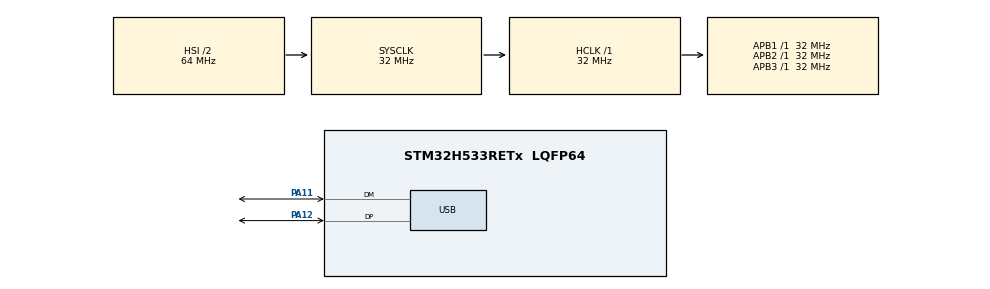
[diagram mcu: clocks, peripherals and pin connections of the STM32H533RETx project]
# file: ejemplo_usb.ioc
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BOOTPATH.BootPathName=LEGACY
BOOTPATH.UserSelectedBootPath=LEGACY
CORTEX_M33_NS.Number-Cortex_Memory_Protection_Unit_Region0_OTP_RO_AREAS_Settings=MPU_REGION_NUMBER0
CORTEX_M33_NS.default_mode_Activation=1
CORTEX_M33_NS.userName=CORTEX_M33
Mcu.Family=STM32H5
Mcu.Name=STM32H533RETx
Mcu.Package=LQFP64
NUCLEO-H533RE.LD4=true
NUCLEO-H533RE.VCP=true
NVIC.PriorityGroup=NVIC_PRIORITYGROUP_4
NVIC.USB_DRD_FS_IRQn=true\:0\:0\:false\:false\:true\:true\:true\:true
PA11.Mode=Device
PA11.Signal=USB_DM
PA12.Mode=Device
PA12.Signal=USB_DP
PA13(JTMS/SWDIO).GPIO_Label=SWDIO
PA13(JTMS/SWDIO).Signal=DEBUG_JTMS-SWDIO
PA14(JTCK/SWCLK).GPIO_Label=SWCLK
PA14(JTCK/SWCLK).Signal=DEBUG_JTCK-SWCLK
PA15(JTDI).GPIO_Label=JTDI
PA15(JTDI).Signal=DEBUG_JTDI
PA2.Signal=USART2_TX
PA3.Signal=USART2_RX
PB3(JTDO/TRACESWO).GPIO_Label=SWO
PB3(JTDO/TRACESWO).Signal=DEBUG_JTDO-SWO
ProjectManager.HeapSize=0x200
ProjectManager.StackSize=0x400
ProjectManager.TargetToolchain=STM32CubeIDE
RCC.ADCFreq_Value=32000000
RCC.AHBFreq_Value=32000000
RCC.APB1Freq_Value=32000000
RCC.APB1TimFreq_Value=32000000
RCC.APB2Freq_Value=32000000
RCC.APB2TimFreq_Value=32000000
RCC.APB3Freq_Value=32000000
RCC.CSI_VALUE=4000000
RCC.CortexFreq_Value=32000000
RCC.EPOD_VALUE=4000000
RCC.HCLKFreq_Value=32000000
RCC.HSE_VALUE=25000000
RCC.HSI48_VALUE=48000000
RCC.HSI_VALUE=64000000
RCC.LSE_VALUE=32768
RCC.LSIRC_VALUE=32000
RCC.SYSCLKFreq_VALUE=32000000
RCC.USBFreq_Value=48000000
RCC.VCOOutputFreq_Value=516000000
USB.VirtualMode=Device_Only
USBX.Core_System=1
USBX.UX_APP_MEM_POOL_SIZE_STANDALONE=8192
USBX.UX_DEVICE_ENABLED_FS=1
USBX.UX_DEVICE_STORAGE=1
USBX.UX_Device_CoreStack=1
USBX.UX_enabled_FS=1
VP_BOOTPATH_VS_BOOTPATH.Mode=BP_Activate
VP_CORTEX_M33_NS_VS_Hclk.Mode=Hclk_Mode
VP_ICACHE_VS_ICACHE.Mode=DirectMappedCache
VP_MEMORYMAP_VS_MEMORYMAP.Mode=CurAppReg
VP_NUCLEO-H533RE_VS_BSP_COMMON.Mode=COMMON
VP_PWR_VS_LPOM.Mode=PowerOptimisation
VP_PWR_VS_SECSignals.Mode=Security/Privilege
VP_USBX_Core_System.Mode=Core_System
VP_USBX_UX\ Device\ CoreStack_FS.Mode=UX_Device_CoreStack
VP_USBX_UX\ Device\ MSC_FS.Mode=UX_Device_class_MSC_FS_HS
board=NUCLEO-H533RE

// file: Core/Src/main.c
/* USER CODE BEGIN Header */
/**
  ******************************************************************************
  * @file           : main.c
  * @brief          : Main program body
  ******************************************************************************
  * @attention
  *
  * Copyright (c) 2026 STMicroelectronics.
  * All rights reserved.
  *
  * This software is licensed under terms that can be found in the LICENSE file
  * in the root directory of this software component.
  * If no LICENSE file comes with this software, it is provided AS-IS.
  *
  ******************************************************************************
  */
/* USER CODE END Header */
#include "main.h"
#include "app_usbx.h"

COM_InitTypeDef BspCOMInit;

PCD_HandleTypeDef hpcd_USB_DRD_FS;

void SystemClock_Config(void);
static void MPU_Config(void);
static void MX_GPIO_Init(void);
static void MX_ICACHE_Init(void);
static void MX_USB_PCD_Init(void);

/* USER CODE BEGIN 0 */
uint32_t tiempo;
uint32_t contador;
/* USER CODE END 0 */

int main(void)
{

  /* MCU Configuration--------------------------------------------------------*/

  /* MPU Configuration--------------------------------------------------------*/
  MPU_Config();

  /* Reset of all peripherals, Initializes the Flash interface and the Systick. */
  HAL_Init();

  /* Configure the system clock */
  SystemClock_Config();

  /* USER CODE BEGIN SysInit */
  BspCOMInit.BaudRate   = 115200;
  BspCOMInit.WordLength = COM_WORDLENGTH_8B;
  BspCOMInit.StopBits   = COM_STOPBITS_1;
  BspCOMInit.Parity     = COM_PARITY_NONE;
  BspCOMInit.HwFlowCtl  = COM_HWCONTROL_NONE;
  if (BSP_COM_Init(COM1, &BspCOMInit) != BSP_ERROR_NONE)
  {
    Error_Handler();
  }
  /* USER CODE END SysInit */

  /* Initialize all configured peripherals */
  MX_GPIO_Init();
  MX_ICACHE_Init();
  MX_USB_PCD_Init();
  /* NOTA CALU: esto lo estoy agregando a partir de lo que sale de este posteo en el foro st:
  https://community.st.com/stm32-mcus-embedded-software-32/usbx-on-stm32h5-cdc-can-t-open-port-160902 */
HAL_PCDEx_PMAConfig(&hpcd_USB_DRD_FS, 0x00, PCD_SNG_BUF, 0x08);
HAL_PCDEx_PMAConfig(&hpcd_USB_DRD_FS, 0x80, PCD_SNG_BUF, 0x58);
HAL_PCDEx_PMAConfig(&hpcd_USB_DRD_FS, 0x81, PCD_SNG_BUF, 0xC0);
HAL_PCDEx_PMAConfig(&hpcd_USB_DRD_FS, 0x02, PCD_SNG_BUF, 0x100);
printf("[MAIN] antes de MX_USBX_Init\r\n");
UINT r = MX_USBX_Init();
printf("[MAIN] MX_USBX_Init ret = 0x%08lX\r\n", (unsigned long)r);
  // MX_USBX_Init();
  /* USER CODE BEGIN 2 */
  HAL_PCD_Start(&hpcd_USB_DRD_FS); //Agregado por calu
  /* USER CODE END 2 */

  /* Initialize leds */
  BSP_LED_Init(LED_GREEN);

  /* Initialize COM1 port (115200, 8 bits (7-bit data + 1 stop bit), no parity */

  /* Infinite loop */
  /* USER CODE BEGIN WHILE */
  tiempo = HAL_GetTick();
  while (1)
  {
	  ux_device_stack_tasks_run();
	  if ((HAL_GetTick() - tiempo) >= 500) {
	    tiempo = HAL_GetTick();
	    contador = contador + 1;
	    printf("Contador: %lu \r\n", contador);
	    BSP_LED_Toggle(LED_GREEN);
	  }
    /* USER CODE END WHILE */

  }
}

void SystemClock_Config(void)
{
  RCC_OscInitTypeDef RCC_OscInitStruct = {0};
  RCC_ClkInitTypeDef RCC_ClkInitStruct = {0};

  /** Configure the main internal regulator output voltage
  */
  __HAL_PWR_VOLTAGESCALING_CONFIG(PWR_REGULATOR_VOLTAGE_SCALE3);

  while(!__HAL_PWR_GET_FLAG(PWR_FLAG_VOSRDY)) {}

  /** Initializes the RCC Oscillators according to the specified parameters
  * in the RCC_OscInitTypeDef structure.
  */
  RCC_OscInitStruct.OscillatorType = RCC_OSCILLATORTYPE_HSI48|RCC_OSCILLATORTYPE_HSI;
  RCC_OscInitStruct.HSIState = RCC_HSI_ON;
  RCC_OscInitStruct.HSIDiv = RCC_HSI_DIV2;
  RCC_OscInitStruct.HSICalibrationValue = RCC_HSICALIBRATION_DEFAULT;
  RCC_OscInitStruct.HSI48State = RCC_HSI48_ON;
  RCC_OscInitStruct.PLL.PLLState = RCC_PLL_NONE;
  if (HAL_RCC_OscConfig(&RCC_OscInitStruct) != HAL_OK)
  {
    Error_Handler();
  }

  /** Initializes the CPU, AHB and APB buses clocks
  */
  RCC_ClkInitStruct.ClockType = RCC_CLOCKTYPE_HCLK|RCC_CLOCKTYPE_SYSCLK
                              |RCC_CLOCKTYPE_PCLK1|RCC_CLOCKTYPE_PCLK2
                              |RCC_CLOCKTYPE_PCLK3;
  RCC_ClkInitStruct.SYSCLKSource = RCC_SYSCLKSOURCE_HSI;
  RCC_ClkInitStruct.AHBCLKDivider = RCC_SYSCLK_DIV1;
  RCC_ClkInitStruct.APB1CLKDivider = RCC_HCLK_DIV1;
  RCC_ClkInitStruct.APB2CLKDivider = RCC_HCLK_DIV1;
  RCC_ClkInitStruct.APB3CLKDivider = RCC_HCLK_DIV1;

  if (HAL_RCC_ClockConfig(&RCC_ClkInitStruct, FLASH_LATENCY_1) != HAL_OK)
  {
    Error_Handler();
  }

  /** Configure the programming delay
  */
  __HAL_FLASH_SET_PROGRAM_DELAY(FLASH_PROGRAMMING_DELAY_0);
}

static void MX_ICACHE_Init(void)
{

  /** Enable instruction cache in 1-way (direct mapped cache)
  */
  if (HAL_ICACHE_ConfigAssociativityMode(ICACHE_1WAY) != HAL_OK)
  {
    Error_Handler();
  }
  if (HAL_ICACHE_Enable() != HAL_OK)
  {
    Error_Handler();
  }

}

static void MX_USB_PCD_Init(void)
{

  hpcd_USB_DRD_FS.Instance = USB_DRD_FS;
  hpcd_USB_DRD_FS.Init.dev_endpoints = 8;
  hpcd_USB_DRD_FS.Init.speed = USBD_FS_SPEED;
  hpcd_USB_DRD_FS.Init.phy_itface = PCD_PHY_EMBEDDED;
  hpcd_USB_DRD_FS.Init.Sof_enable = DISABLE;
  hpcd_USB_DRD_FS.Init.low_power_enable = DISABLE;
  hpcd_USB_DRD_FS.Init.lpm_enable = DISABLE;
  hpcd_USB_DRD_FS.Init.battery_charging_enable = DISABLE;
  hpcd_USB_DRD_FS.Init.vbus_sensing_enable = DISABLE;
  hpcd_USB_DRD_FS.Init.bulk_doublebuffer_enable = DISABLE;
  hpcd_USB_DRD_FS.Init.iso_singlebuffer_enable = DISABLE;
  if (HAL_PCD_Init(&hpcd_USB_DRD_FS) != HAL_OK)
  {
    Error_Handler();
  }

}

static void MX_GPIO_Init(void)
{

  /* GPIO Ports Clock Enable */
  __HAL_RCC_GPIOA_CLK_ENABLE();
  __HAL_RCC_GPIOB_CLK_ENABLE();

}

 /* MPU Configuration */

void MPU_Config(void)
{
  MPU_Region_InitTypeDef MPU_InitStruct = {0};
  MPU_Attributes_InitTypeDef MPU_AttributesInit = {0};

  /* Disables the MPU */
  HAL_MPU_Disable();

  /** Initializes and configures the Region 0 and the memory to be protected
  */
  MPU_InitStruct.Enable = MPU_REGION_ENABLE;
  MPU_InitStruct.Number = MPU_REGION_NUMBER0;
  MPU_InitStruct.BaseAddress = 0x08FFF000;
  MPU_InitStruct.LimitAddress = 0x08FFFFFF;
  MPU_InitStruct.AttributesIndex = MPU_ATTRIBUTES_NUMBER0;
  MPU_InitStruct.AccessPermission = MPU_REGION_ALL_RO;
  MPU_InitStruct.DisableExec = MPU_INSTRUCTION_ACCESS_DISABLE;
  MPU_InitStruct.IsShareable = MPU_ACCESS_NOT_SHAREABLE;

  HAL_MPU_ConfigRegion(&MPU_InitStruct);

  /** Initializes and configures the Attribute 0 and the memory to be protected
  */
  MPU_AttributesInit.Number = MPU_ATTRIBUTES_NUMBER0;
  MPU_AttributesInit.Attributes = INNER_OUTER(MPU_NOT_CACHEABLE);

  HAL_MPU_ConfigMemoryAttributes(&MPU_AttributesInit);
  /* Enables the MPU */
  HAL_MPU_Enable(MPU_PRIVILEGED_DEFAULT);

}

void Error_Handler(void)
{
  __disable_irq();
  while (1)
  {
  }
}
